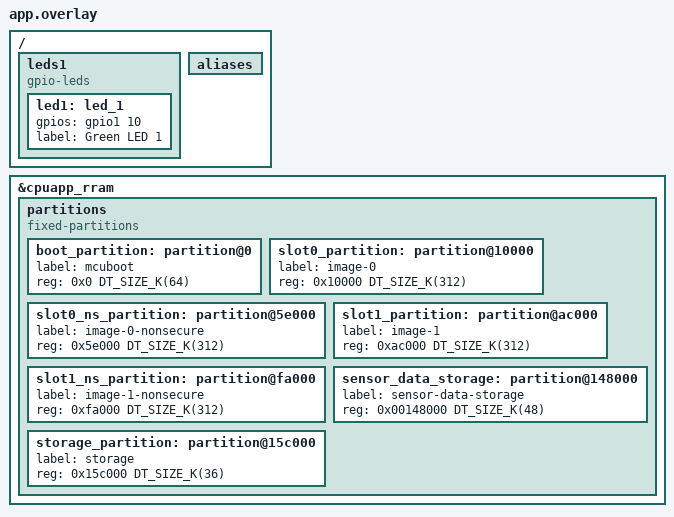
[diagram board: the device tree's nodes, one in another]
/*
 * Copyright (c) 2023 Nordic Semiconductor ASA
 *
 * SPDX-License-Identifier: LicenseRef-Nordic-5-Clause
 */

/{
	/delete-node/ leds;

	leds1 {
		compatible = "gpio-leds";
		led1: led_1 {
			gpios = <&gpio1 10 GPIO_ACTIVE_HIGH>;
			label = "Green LED 1";
		};
	};

	aliases {
		/delete-property/ led0;
		/delete-property/ led1;
		/delete-property/ led2;
		/delete-property/ led3;
		/delete-property/ sw0;
	};
};

/delete-node/ &button0;	// P1.13 is bmi270 chip select signal

 &cpuapp_rram {
	/delete-node/ partitions;
	partitions {
		compatible = "fixed-partitions";
		#address-cells = <1>;
		#size-cells = <1>;
		boot_partition: partition@0 {
			label = "mcuboot";
			reg = <0x0 DT_SIZE_K(64)>;
		};
		slot0_partition: partition@10000 {
			label = "image-0";
			reg = <0x10000 DT_SIZE_K(312)>;
		};
		slot0_ns_partition: partition@5e000 {
			label = "image-0-nonsecure";
			reg = <0x5e000 DT_SIZE_K(312)>;
		};
		slot1_partition: partition@ac000 {
			label = "image-1";
			reg = <0xac000 DT_SIZE_K(312)>;
		};
		slot1_ns_partition: partition@fa000 {
			label = "image-1-nonsecure";
			reg = <0xfa000 DT_SIZE_K(312)>;
		};
		sensor_data_storage: partition@148000 {
			label = "sensor-data-storage";
			reg = <0x00148000 DT_SIZE_K(48)>;
		};
		/* 32k from 0x154000 to 0x15bfff reserved for TF-M partitions */
		storage_partition: partition@15c000 {
			label = "storage";
			reg = <0x15c000 DT_SIZE_K(36)>;
		};
	};
 };
